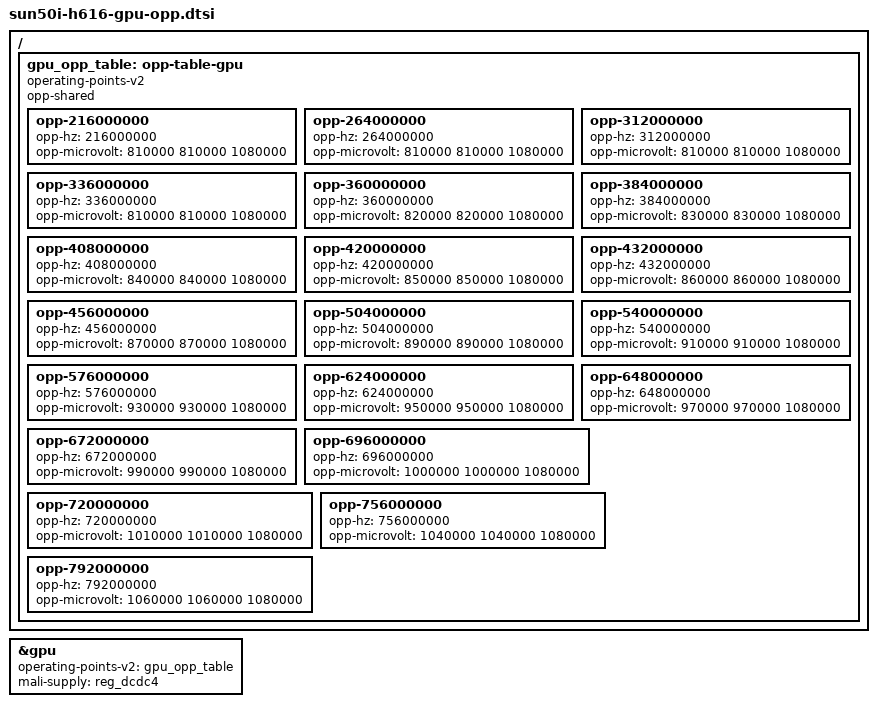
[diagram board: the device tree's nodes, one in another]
// SPDX-License-Identifier: (GPL-2.0+ OR MIT)
// Copyright (C) 2024 Wiren Board

/ {
    gpu_opp_table: opp-table-gpu {
        compatible = "operating-points-v2";
        opp-shared;

        /* slow */
        opp-216000000 { opp-hz = /bits/ 64 <216000000>; opp-microvolt = <810000 810000 1080000>; };
        opp-264000000 { opp-hz = /bits/ 64 <264000000>; opp-microvolt = <810000 810000 1080000>; };
        opp-312000000 { opp-hz = /bits/ 64 <312000000>; opp-microvolt = <810000 810000 1080000>; };
        opp-336000000 { opp-hz = /bits/ 64 <336000000>; opp-microvolt = <810000 810000 1080000>; };
        opp-360000000 { opp-hz = /bits/ 64 <360000000>; opp-microvolt = <820000 820000 1080000>; };
        opp-384000000 { opp-hz = /bits/ 64 <384000000>; opp-microvolt = <830000 830000 1080000>; };
        opp-408000000 { opp-hz = /bits/ 64 <408000000>; opp-microvolt = <840000 840000 1080000>; };
        opp-420000000 { opp-hz = /bits/ 64 <420000000>; opp-microvolt = <850000 850000 1080000>; };
        opp-432000000 { opp-hz = /bits/ 64 <432000000>; opp-microvolt = <860000 860000 1080000>; };

        /* middle */
        opp-456000000 { opp-hz = /bits/ 64 <456000000>; opp-microvolt = <870000 870000 1080000>; };
        opp-504000000 { opp-hz = /bits/ 64 <504000000>; opp-microvolt = <890000 890000 1080000>; };
        opp-540000000 { opp-hz = /bits/ 64 <540000000>; opp-microvolt = <910000 910000 1080000>; };
        opp-576000000 { opp-hz = /bits/ 64 <576000000>; opp-microvolt = <930000 930000 1080000>; };
        opp-624000000 { opp-hz = /bits/ 64 <624000000>; opp-microvolt = <950000 950000 1080000>; };

        /* middle-middle */
        opp-648000000 { opp-hz = /bits/ 64 <648000000>; opp-microvolt = <970000 970000 1080000>; };
        opp-672000000 { opp-hz = /bits/ 64 <672000000>; opp-microvolt = <990000 990000 1080000>; };
        opp-696000000 { opp-hz = /bits/ 64 <696000000>; opp-microvolt = <1000000 1000000 1080000>; };
        opp-720000000 { opp-hz = /bits/ 64 <720000000>; opp-microvolt = <1010000 1010000 1080000>; };

        /* high */
        opp-756000000 { opp-hz = /bits/ 64 <756000000>; opp-microvolt = <1040000 1040000 1080000>; };
        opp-792000000 { opp-hz = /bits/ 64 <792000000>; opp-microvolt = <1060000 1060000 1080000>; };

        /* при желании можно попробовать 816/840/864, но это уже зависит от экземпляра кристалла и теплоотвода */
    };
};

&gpu {
    operating-points-v2 = <&gpu_opp_table>;
    mali-supply = <&reg_dcdc4>;      /* очень важно для применения напряжений */
    #cooling-cells = <2>;            /* для thermal → devfreq-cooling */
};

